# ddr32ss_EMIF_CTLCFG_0F308000h register map
Vendor: Texas Instruments
Registers are 32-bit, read-write, reset 0x0 unless marked. A register's access mark holds for its fields unless they carry their own. Offsets are as the file gives them; [hi:lo] are bit positions; lines under a group give offsets from that group; {n}, {i} and the like mark numbered series.

## emif_ctlcfg (part 4 of 13)
0x480 emif_ctlcfg_DENALI_CTL_288
  [31:0] BIST_DATA_MASK_1 — Mask applied to data for BIST error checking. Bit [0] controls memory data path bit [0], bit [1] controls memory data path bit [1], etc. Set each bit to 1 to mask. Reset Source: ctl_amod_g_rst_n
0x484 emif_ctlcfg_DENALI_CTL_289
  [2:0] BIST_TEST_MODE — Sets the BIST test mode. Value of 0 specifies standard BIST operation, value of 1 specifies a reduced BIST operation, value of 2 specifies a self-refresh retention test, value of 3 specifies an idle retention test, and value of 4 specifies memory initalization function. All other values are reserved. Reset Source: ctl_amod_g_rst_n
{0x0+4i} emif_ctlcfg_DENALI_CTL_{i} (i=290..293)
  [31:0] BIST_DATA_PATTERN_{i-290} — Data pattern to be used when the BIST_TEST_MODE parameter is programmed to 1, 2, 3 or 4. Only data corresponding to active portion of core word will be used while inactive portion will be ignored. Reset Source: ctl_amod_g_rst_n
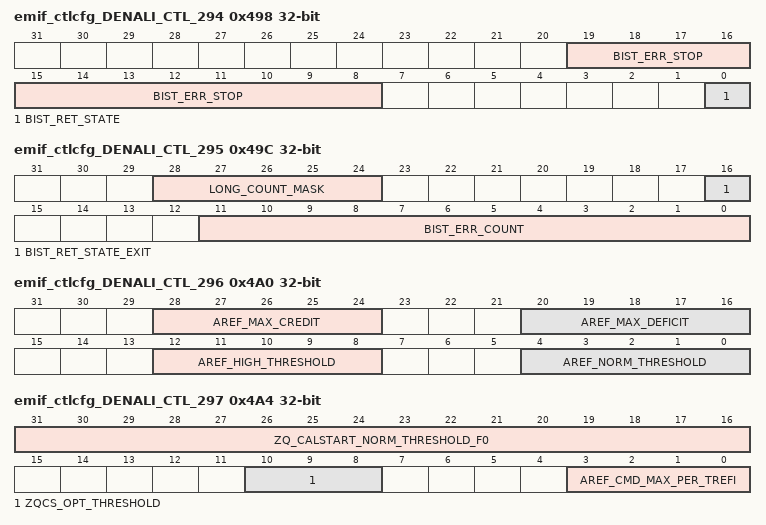
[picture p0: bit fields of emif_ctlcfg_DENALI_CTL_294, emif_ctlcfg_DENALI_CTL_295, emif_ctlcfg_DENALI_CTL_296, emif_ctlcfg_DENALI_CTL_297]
0x498 emif_ctlcfg_DENALI_CTL_294 access per field
  [19:8] BIST_ERR_STOP rw — Defines the maximum number of error occurrences allowed prior to quitting when the BIST_TEST_MODE parameter is programmed to 1, 2 or 3. A value of 0 will allow the test to run to completion. Reset Source: ctl_amod_g_rst_n
  [0] BIST_RET_STATE ro — Indicates if BIST is in a retention wait state, used when the BIST_TEST_MODE parameter is programmed to 2 or 3. Value of 1 indicates BIST is waiting. READ-ONLY Reset Source: ctl_amod_g_rst_n
0x49C emif_ctlcfg_DENALI_CTL_295 access per field
  [28:24] LONG_COUNT_MASK rw — Reduces the length of the long counter from 1024 cycles. The only supported values are 0x00 [1024 cycles], 0x10 [512 clocks], 0x18 [256 clocks], 0x1C [128 clocks], 0x1E [64 clocks] and 0x1F [32 clocks]. Reset Source: ctl_amod_g_rst_n
  [16] BIST_RET_STATE_EXIT wo — Exit self-refresh or idle retention state, used when the BIST_TEST_MODE parameter is programmed to 2 or 3. Set to 1 to trigger. WRITE-ONLY Reset Source: ctl_amod_g_rst_n
  [11:0] BIST_ERR_COUNT ro — Indicates the number of BIST errors found when the BIST_TEST_MODE parameter is programmed to 1, 2 or 3. READ-ONLY Reset Source: ctl_amod_g_rst_n
0x4A0 emif_ctlcfg_DENALI_CTL_296
  [28:24] AREF_MAX_CREDIT — AREF number of posted refreshes until the maximum number of refresh credits has been reached. Reset Source: ctl_amod_g_rst_n
  [20:16] AREF_MAX_DEFICIT — AREF number of pending refreshes until the maximum number of refreshes has been exceeded. Reset Source: ctl_amod_g_rst_n
  [12:8] AREF_HIGH_THRESHOLD — AREF number of pending refreshes until the high priority request is asserted. Reset Source: ctl_amod_g_rst_n
  [4:0] AREF_NORM_THRESHOLD — AREF number of pending refreshes until the normal priority request is asserted. Reset Source: ctl_amod_g_rst_n
0x4A4 emif_ctlcfg_DENALI_CTL_297
  [31:16] ZQ_CALSTART_NORM_THRESHOLD_F0 — ZQ START number of long counts until the normal priority request is asserted. This value should be scaled based on the number of ranks [chip selects] the controller handles. The more chip selects there are, the more rotations there are to go through, and the smaller this threshold should be. FC=0 Reset Source: ctl_amod_g_rst_n
  [10:8] ZQCS_OPT_THRESHOLD — Number of clocks before ZQCS expires when the ZQ task will deassert its request for optimal command to command turn-around timing. Reset Source: ctl_amod_g_rst_n
  [3:0] AREF_CMD_MAX_PER_TREFI — Sets the maximum number of auto-refreshes that will be executed in a TREFI period - both normal and high priority. This does not prevent refreshes generated by sub-task requests such as a self-refresh exit and enter. Reset Source: ctl_amod_g_rst_n
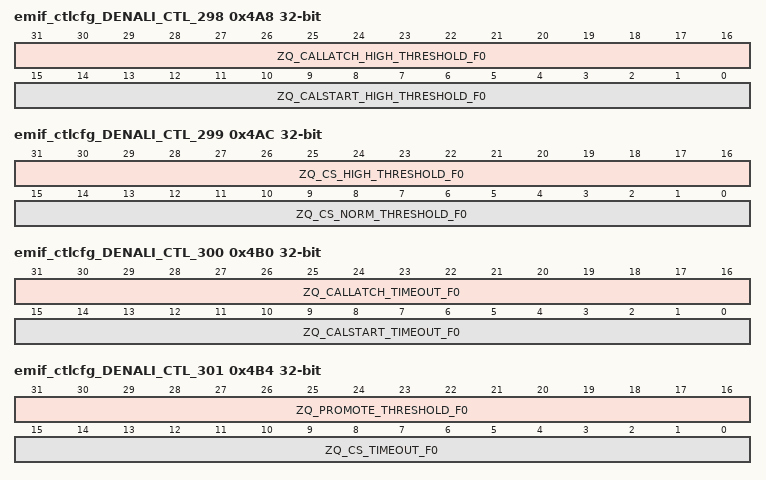
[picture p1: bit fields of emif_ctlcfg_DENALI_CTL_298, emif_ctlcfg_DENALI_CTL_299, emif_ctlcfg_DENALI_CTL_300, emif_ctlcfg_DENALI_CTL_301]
0x4A8 emif_ctlcfg_DENALI_CTL_298
  [31:16] ZQ_CALLATCH_HIGH_THRESHOLD_F0 — ZQ LATCH number of long counts until the high priority request is asserted. FC=0 Reset Source: ctl_amod_g_rst_n
  [15:0] ZQ_CALSTART_HIGH_THRESHOLD_F0 — ZQ START number of long counts until the high priority request is asserted. FC=0 Reset Source: ctl_amod_g_rst_n
0x4AC emif_ctlcfg_DENALI_CTL_299
  [31:16] ZQ_CS_HIGH_THRESHOLD_F0 — ZQ CS number of long counts until the high priority request is asserted. FC=0 Reset Source: ctl_amod_g_rst_n
  [15:0] ZQ_CS_NORM_THRESHOLD_F0 — ZQ CS number of long counts until the normal priority request is asserted. FC=0 Reset Source: ctl_amod_g_rst_n
0x4B0 emif_ctlcfg_DENALI_CTL_300
  [31:16] ZQ_CALLATCH_TIMEOUT_F0 — ZQ LATCH number of long counts until the timeout is asserted. FC=0 Reset Source: ctl_amod_g_rst_n
  [15:0] ZQ_CALSTART_TIMEOUT_F0 — ZQ START number of long counts until the timeout is asserted. FC=0 Reset Source: ctl_amod_g_rst_n
0x4B4 emif_ctlcfg_DENALI_CTL_301
  [31:16] ZQ_PROMOTE_THRESHOLD_F0 — ZQ SW promotion number of long counts until the high priority request is asserted. FC=0 Reset Source: ctl_amod_g_rst_n
  [15:0] ZQ_CS_TIMEOUT_F0 — ZQ CS number of long counts until the timeout is asserted. FC=0 Reset Source: ctl_amod_g_rst_n
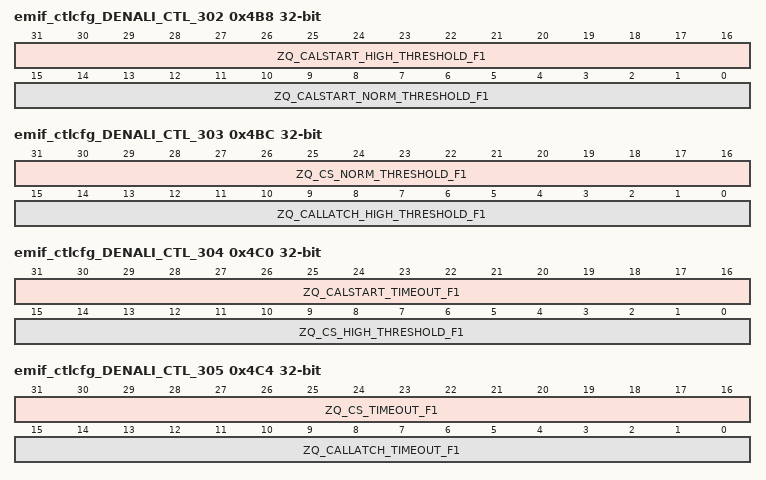
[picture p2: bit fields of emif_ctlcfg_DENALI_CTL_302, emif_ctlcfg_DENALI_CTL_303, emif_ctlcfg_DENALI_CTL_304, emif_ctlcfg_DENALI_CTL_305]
0x4B8 emif_ctlcfg_DENALI_CTL_302
  [31:16] ZQ_CALSTART_HIGH_THRESHOLD_F1 — ZQ START number of long counts until the high priority request is asserted. FC=1 Reset Source: ctl_amod_g_rst_n
  [15:0] ZQ_CALSTART_NORM_THRESHOLD_F1 — ZQ START number of long counts until the normal priority request is asserted. This value should be scaled based on the number of ranks [chip selects] the controller handles. The more chip selects there are, the more rotations there are to go through, and the smaller this threshold should be. FC=1 Reset Source: ctl_amod_g_rst_n
0x4BC emif_ctlcfg_DENALI_CTL_303
  [31:16] ZQ_CS_NORM_THRESHOLD_F1 — ZQ CS number of long counts until the normal priority request is asserted. FC=1 Reset Source: ctl_amod_g_rst_n
  [15:0] ZQ_CALLATCH_HIGH_THRESHOLD_F1 — ZQ LATCH number of long counts until the high priority request is asserted. FC=1 Reset Source: ctl_amod_g_rst_n
0x4C0 emif_ctlcfg_DENALI_CTL_304
  [31:16] ZQ_CALSTART_TIMEOUT_F1 — ZQ START number of long counts until the timeout is asserted. FC=1 Reset Source: ctl_amod_g_rst_n
  [15:0] ZQ_CS_HIGH_THRESHOLD_F1 — ZQ CS number of long counts until the high priority request is asserted. FC=1 Reset Source: ctl_amod_g_rst_n
0x4C4 emif_ctlcfg_DENALI_CTL_305
  [31:16] ZQ_CS_TIMEOUT_F1 — ZQ CS number of long counts until the timeout is asserted. FC=1 Reset Source: ctl_amod_g_rst_n
  [15:0] ZQ_CALLATCH_TIMEOUT_F1 — ZQ LATCH number of long counts until the timeout is asserted. FC=1 Reset Source: ctl_amod_g_rst_n
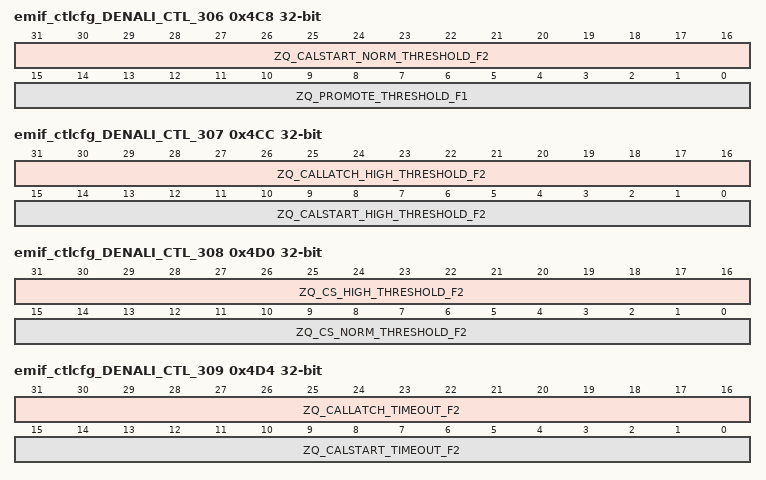
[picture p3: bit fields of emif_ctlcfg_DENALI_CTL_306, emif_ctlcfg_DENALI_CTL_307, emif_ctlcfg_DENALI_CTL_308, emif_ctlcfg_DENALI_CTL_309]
0x4C8 emif_ctlcfg_DENALI_CTL_306
  [31:16] ZQ_CALSTART_NORM_THRESHOLD_F2 — ZQ START number of long counts until the normal priority request is asserted. This value should be scaled based on the number of ranks [chip selects] the controller handles. The more chip selects there are, the more rotations there are to go through, and the smaller this threshold should be. FC=2 Reset Source: ctl_amod_g_rst_n
  [15:0] ZQ_PROMOTE_THRESHOLD_F1 — ZQ SW promotion number of long counts until the high priority request is asserted. FC=1 Reset Source: ctl_amod_g_rst_n
0x4CC emif_ctlcfg_DENALI_CTL_307
  [31:16] ZQ_CALLATCH_HIGH_THRESHOLD_F2 — ZQ LATCH number of long counts until the high priority request is asserted. FC=2 Reset Source: ctl_amod_g_rst_n
  [15:0] ZQ_CALSTART_HIGH_THRESHOLD_F2 — ZQ START number of long counts until the high priority request is asserted. FC=2 Reset Source: ctl_amod_g_rst_n
0x4D0 emif_ctlcfg_DENALI_CTL_308
  [31:16] ZQ_CS_HIGH_THRESHOLD_F2 — ZQ CS number of long counts until the high priority request is asserted. FC=2 Reset Source: ctl_amod_g_rst_n
  [15:0] ZQ_CS_NORM_THRESHOLD_F2 — ZQ CS number of long counts until the normal priority request is asserted. FC=2 Reset Source: ctl_amod_g_rst_n
0x4D4 emif_ctlcfg_DENALI_CTL_309
  [31:16] ZQ_CALLATCH_TIMEOUT_F2 — ZQ LATCH number of long counts until the timeout is asserted. FC=2 Reset Source: ctl_amod_g_rst_n
  [15:0] ZQ_CALSTART_TIMEOUT_F2 — ZQ START number of long counts until the timeout is asserted. FC=2 Reset Source: ctl_amod_g_rst_n
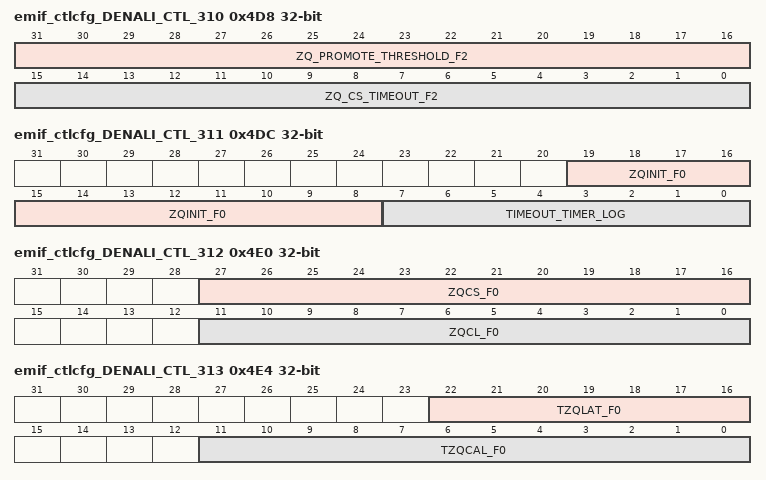
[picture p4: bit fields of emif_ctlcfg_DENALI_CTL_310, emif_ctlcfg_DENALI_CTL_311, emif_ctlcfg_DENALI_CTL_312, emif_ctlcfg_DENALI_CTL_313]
0x4D8 emif_ctlcfg_DENALI_CTL_310
  [31:16] ZQ_PROMOTE_THRESHOLD_F2 — ZQ SW promotion number of long counts until the high priority request is asserted. FC=2 Reset Source: ctl_amod_g_rst_n
  [15:0] ZQ_CS_TIMEOUT_F2 — ZQ CS number of long counts until the timeout is asserted. FC=2 Reset Source: ctl_amod_g_rst_n
0x4DC emif_ctlcfg_DENALI_CTL_311 access per field
  [19:8] ZQINIT_F0 rw — Number of cycles needed for a ZQINIT command. FC=0 Reset Source: ctl_amod_g_rst_n
  [7:0] TIMEOUT_TIMER_LOG ro — Reflects which timers experienced a timeout error [or had an uncleared error] when the timeout interrupt fired. Bit [0] correlates to a ZQ cal init, cs, cl, or reset FM timeout. Bit [1] correlates to the ZQ calstart FM timeout. Bit [2] correlates to the ZQ callatch FM timeout. Bit [3] correlates to the MRR temperature check FM timeout. Bit [4] correlates to the DQS oscillator FM timeout. Bit [5] correlates to the DFI update FM timeout. Bit [6] correlates to the low power interface wakeup timeout. Bit [7] correlates to the auto refresh max deficit timeout. READ-ONLY Reset Source: ctl_amod_g_rst_n
0x4E0 emif_ctlcfg_DENALI_CTL_312
  [27:16] ZQCS_F0 — Number of cycles needed for a ZQCS command. FC=0 Reset Source: ctl_amod_g_rst_n
  [11:0] ZQCL_F0 — Number of cycles needed for a ZQCL command. FC=0 Reset Source: ctl_amod_g_rst_n
0x4E4 emif_ctlcfg_DENALI_CTL_313
  [22:16] TZQLAT_F0 — Holds the DRAM ZQLAT value in cycles. FC=0 Reset Source: ctl_amod_g_rst_n
  [11:0] TZQCAL_F0 — Holds the DRAM ZQCAL value in cycles. FC=0 Reset Source: ctl_amod_g_rst_n
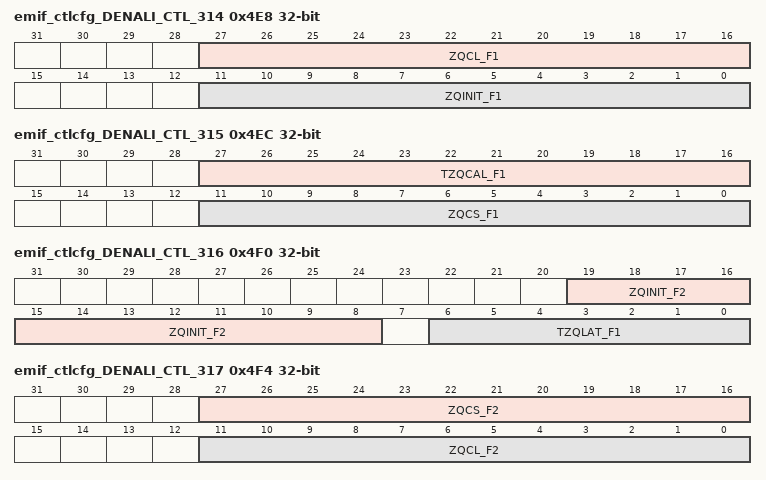
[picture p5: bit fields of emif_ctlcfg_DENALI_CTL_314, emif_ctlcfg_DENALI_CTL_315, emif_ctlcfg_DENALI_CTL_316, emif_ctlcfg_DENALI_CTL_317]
0x4E8 emif_ctlcfg_DENALI_CTL_314
  [27:16] ZQCL_F1 — Number of cycles needed for a ZQCL command. FC=1 Reset Source: ctl_amod_g_rst_n
  [11:0] ZQINIT_F1 — Number of cycles needed for a ZQINIT command. FC=1 Reset Source: ctl_amod_g_rst_n
0x4EC emif_ctlcfg_DENALI_CTL_315
  [27:16] TZQCAL_F1 — Holds the DRAM ZQCAL value in cycles. FC=1 Reset Source: ctl_amod_g_rst_n
  [11:0] ZQCS_F1 — Number of cycles needed for a ZQCS command. FC=1 Reset Source: ctl_amod_g_rst_n
0x4F0 emif_ctlcfg_DENALI_CTL_316
  [19:8] ZQINIT_F2 — Number of cycles needed for a ZQINIT command. FC=2 Reset Source: ctl_amod_g_rst_n
  [6:0] TZQLAT_F1 — Holds the DRAM ZQLAT value in cycles. FC=1 Reset Source: ctl_amod_g_rst_n
0x4F4 emif_ctlcfg_DENALI_CTL_317
  [27:16] ZQCS_F2 — Number of cycles needed for a ZQCS command. FC=2 Reset Source: ctl_amod_g_rst_n
  [11:0] ZQCL_F2 — Number of cycles needed for a ZQCL command. FC=2 Reset Source: ctl_amod_g_rst_n
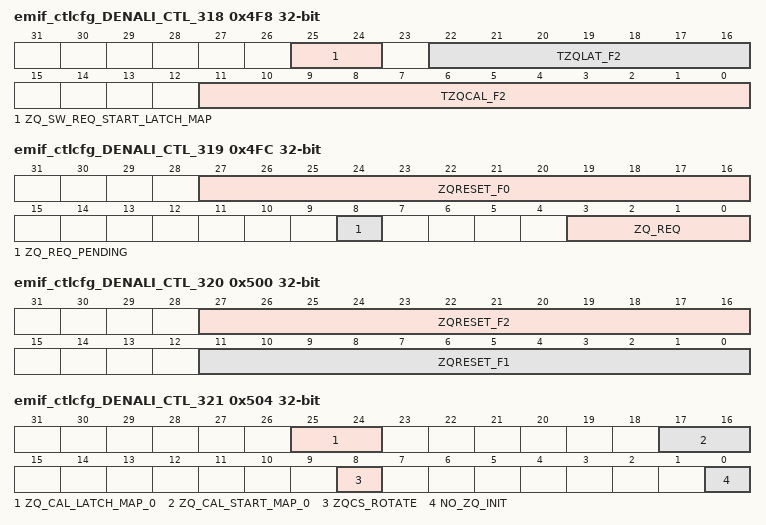
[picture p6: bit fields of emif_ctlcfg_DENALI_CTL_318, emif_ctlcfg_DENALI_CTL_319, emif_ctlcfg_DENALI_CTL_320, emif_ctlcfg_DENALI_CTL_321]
0x4F8 emif_ctlcfg_DENALI_CTL_318
  [25:24] ZQ_SW_REQ_START_LATCH_MAP — Specifies which chip selects will simultaneously receive a ZQ start or latch command once the ZQ_REQ parameter is written with a ZQ Start or ZQ Latch command. Reset Source: ctl_amod_g_rst_n
  [22:16] TZQLAT_F2 — Holds the DRAM ZQLAT value in cycles. FC=2 Reset Source: ctl_amod_g_rst_n
  [11:0] TZQCAL_F2 — Holds the DRAM ZQCAL value in cycles. FC=2 Reset Source: ctl_amod_g_rst_n
0x4FC emif_ctlcfg_DENALI_CTL_319 access per field
  [27:16] ZQRESET_F0 rw — Number of cycles needed for a ZQRESET command. FC=0 Reset Source: ctl_amod_g_rst_n
  [8] ZQ_REQ_PENDING ro — Indicates that a ZQ command is currently in progress or waiting to run. Value of 1 indicates command in progress or waiting to run. When this is asserted, no writes to ZQ_REQ should occur. READ-ONLY Reset Source: ctl_amod_g_rst_n
  [3:0] ZQ_REQ wo — User request to initiate a ZQ calibration. Program to 3 for ZQ Start, program to 4 for ZQ Initialization [ZQINIT], program to 5 for ZQ Latch, or program to 8 for ZQ Reset. Clearing to 0 will not trigger any ZQ command. This parameter should only be written when the ZQ_REQ_PENDING parameter is cleared to 0. WRITE-ONLY Reset Source: ctl_amod_g_rst_n
0x500 emif_ctlcfg_DENALI_CTL_320
  [27:16] ZQRESET_F2 — Number of cycles needed for a ZQRESET command. FC=2 Reset Source: ctl_amod_g_rst_n
  [11:0] ZQRESET_F1 — Number of cycles needed for a ZQRESET command. FC=1 Reset Source: ctl_amod_g_rst_n
0x504 emif_ctlcfg_DENALI_CTL_321
  [25:24] ZQ_CAL_LATCH_MAP_0 — Defines which chip select[s] will receive ZQ calibration latch commands simultaneously on iteration 0 of the ZQ LATCH initialization and periodic command sequences. Clear to all zeros for no ZQ LATCH commands. CS=0 Reset Source: ctl_amod_g_rst_n
  [17:16] ZQ_CAL_START_MAP_0 — Defines which chip select[s] will receive ZQ calibration start commands simultaneously on iteration 0 of the ZQ START initialization and periodic command sequences. Clear to all zeros for no ZQ START commands. CS=0 Reset Source: ctl_amod_g_rst_n
  [8] ZQCS_ROTATE — For memories that perform ZQ short commands [ZQCS], selects whether a ZQCS command will calibrate just one chip select or all chip selects. When rotation is off, all chip selects will be calibrated, requiring a longer time frame, but ZQ calibration will need to be performed less frequently. Set to 1 for rotating CS. For ZQ start/latch memories, this parameter is ignored. Reset Source: ctl_amod_g_rst_n
  [0] NO_ZQ_INIT — Disable ZQ operations during initialization. Set to 1 to disable. Reset Source: ctl_amod_g_rst_n
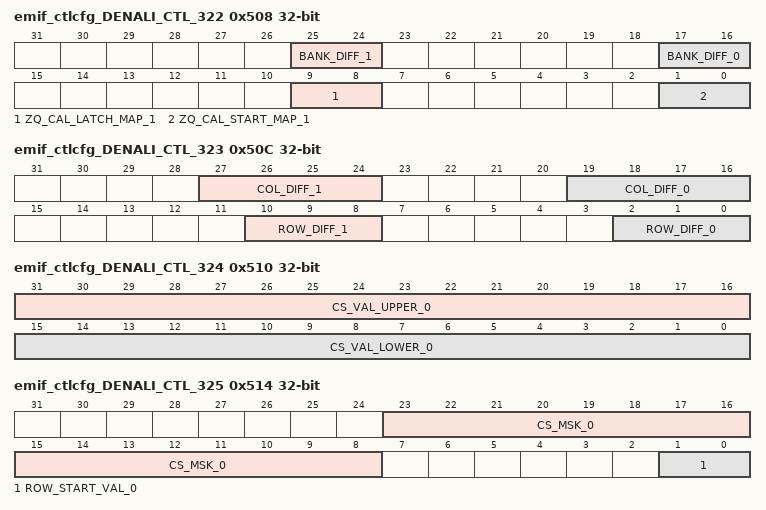
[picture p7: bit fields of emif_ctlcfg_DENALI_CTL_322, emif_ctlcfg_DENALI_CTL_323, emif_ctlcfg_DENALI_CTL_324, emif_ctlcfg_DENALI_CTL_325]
0x508 emif_ctlcfg_DENALI_CTL_322
  [25:24] BANK_DIFF_1 — Encoded number of banks on the DRAM[s]. Reset Source: ctl_amod_g_rst_n
  [17:16] BANK_DIFF_0 — Encoded number of banks on the DRAM[s]. Reset Source: ctl_amod_g_rst_n
  [9:8] ZQ_CAL_LATCH_MAP_1 — Defines which chip select[s] will receive ZQ calibration latch commands simultaneously on iteration 1 of the ZQ LATCH initialization and periodic command sequences. Clear to all zeros for no ZQ LATCH commands. CS=1 Reset Source: ctl_amod_g_rst_n
  [1:0] ZQ_CAL_START_MAP_1 — Defines which chip select[s] will receive ZQ calibration start commands simultaneously on iteration 1 of the ZQ START initialization and periodic command sequences. Clear to all zeros for no ZQ START commands. CS=1 Reset Source: ctl_amod_g_rst_n
0x50C emif_ctlcfg_DENALI_CTL_323
  [27:24] COL_DIFF_1 — Difference between number of column pins available and number being used. Reset Source: ctl_amod_g_rst_n
  [19:16] COL_DIFF_0 — Difference between number of column pins available and number being used. Reset Source: ctl_amod_g_rst_n
  [10:8] ROW_DIFF_1 — Difference between number of address pins available and number being used. Reset Source: ctl_amod_g_rst_n
  [2:0] ROW_DIFF_0 — Difference between number of address pins available and number being used. Reset Source: ctl_amod_g_rst_n
0x510 emif_ctlcfg_DENALI_CTL_324
  [31:16] CS_VAL_UPPER_0 — Upper bound address for chip select 0. Reset Source: ctl_amod_g_rst_n
  [15:0] CS_VAL_LOWER_0 — Lower bound address for chip select 0. Reset Source: ctl_amod_g_rst_n
0x514 emif_ctlcfg_DENALI_CTL_325
  [23:8] CS_MSK_0 — Mask applied to the address decode for chip select 0. Reset Source: ctl_amod_g_rst_n
  [1:0] ROW_START_VAL_0 — Row start value for chip select 0. Reset Source: ctl_amod_g_rst_n
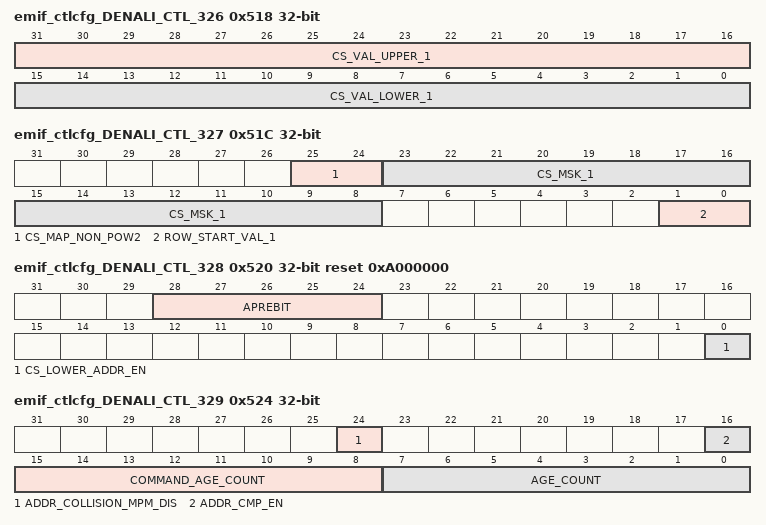
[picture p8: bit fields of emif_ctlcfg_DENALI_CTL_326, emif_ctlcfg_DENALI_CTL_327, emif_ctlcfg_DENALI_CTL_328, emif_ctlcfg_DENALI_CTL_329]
0x518 emif_ctlcfg_DENALI_CTL_326
  [31:16] CS_VAL_UPPER_1 — Upper bound address for chip select 1. Reset Source: ctl_amod_g_rst_n
  [15:0] CS_VAL_LOWER_1 — Lower bound address for chip select 1. Reset Source: ctl_amod_g_rst_n
0x51C emif_ctlcfg_DENALI_CTL_327
  [25:24] CS_MAP_NON_POW2 — Defines which chip selects are non-power-of-2 memory sizes. Reset Source: ctl_amod_g_rst_n
  [23:8] CS_MSK_1 — Mask applied to the address decode for chip select 1. Reset Source: ctl_amod_g_rst_n
  [1:0] ROW_START_VAL_1 — Row start value for chip select 1. Reset Source: ctl_amod_g_rst_n
0x520 emif_ctlcfg_DENALI_CTL_328 reset 0xA000000
  [28:24] APREBIT — Location of the auto pre-charge bit in the DRAM address. Reset Source: ctl_amod_g_rst_n
  [0] CS_LOWER_ADDR_EN — Enables moving the CS field to lower in the address map. When set to 1, the memory address map will be changed to ROW__CS__BANK. Please refer to the limitations before setting this bit. Reset Source: ctl_amod_g_rst_n
0x524 emif_ctlcfg_DENALI_CTL_329
  [24] ADDR_COLLISION_MPM_DIS — Disable address collision detection extension using micro page mask for command queue placement and selection. Set to 1 to disable. Reset Source: ctl_amod_g_rst_n
  [16] ADDR_CMP_EN — Enable address collision detection as a rule for command queue placement. Set to 1 to enable. Reset Source: ctl_amod_g_rst_n
  [15:8] COMMAND_AGE_COUNT — Initial value of individual command aging counters for command aging. Reset Source: ctl_amod_g_rst_n
  [7:0] AGE_COUNT — Initial value of master aging-rate counter for command aging. Reset Source: ctl_amod_g_rst_n
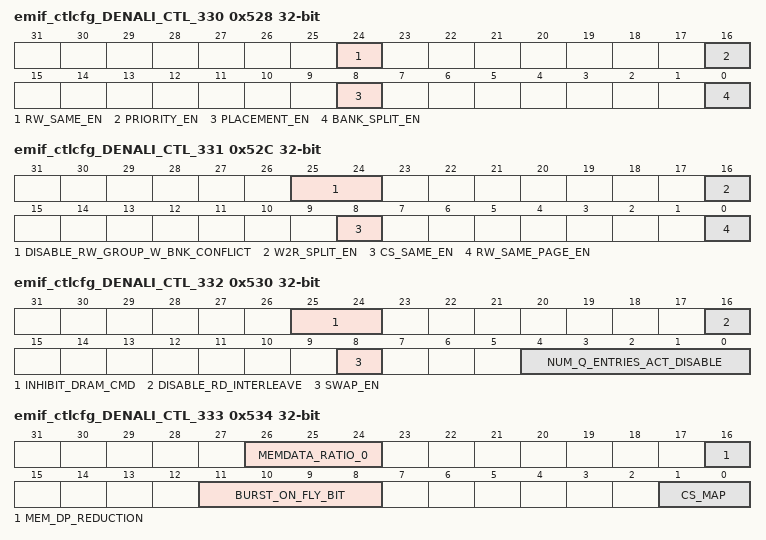
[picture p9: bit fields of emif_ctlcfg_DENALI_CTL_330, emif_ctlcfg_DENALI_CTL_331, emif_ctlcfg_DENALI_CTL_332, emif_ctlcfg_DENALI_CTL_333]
0x528 emif_ctlcfg_DENALI_CTL_330
  [24] RW_SAME_EN — Enable read/write grouping as a rule for command queue placement. Set to 1 to enable. Reset Source: ctl_amod_g_rst_n
  [16] PRIORITY_EN — Enable priority as a rule for command queue placement. Set to 1 to enable. Reset Source: ctl_amod_g_rst_n
  [8] PLACEMENT_EN — Enable placement logic for command queue. Set to 1 to enable. Reset Source: ctl_amod_g_rst_n
  [0] BANK_SPLIT_EN — Enable bank splitting as a rule for command queue placement. Set to 1 to enable. Reset Source: ctl_amod_g_rst_n
0x52C emif_ctlcfg_DENALI_CTL_331
  [25:24] DISABLE_RW_GROUP_W_BNK_CONFLICT — Disables placement to read/write group when grouping creates a bank collision. Bit [0] controls placement next to bank conflict command and bit [1] controls placement 2 away from bank conflict command. Set each bit to 1 to disable. Reset Source: ctl_amod_g_rst_n
  [16] W2R_SPLIT_EN — Enable splitting of commands to the same chip select from a write to a read command as a rule for command queue placement. Reset Source: ctl_amod_g_rst_n
  [8] CS_SAME_EN — Enable chip select grouping when read/write grouping as a rule for command queue placement. This is only valid when the RW_SAME_EN parameter is set. Set to 1 to enable. Reset Source: ctl_amod_g_rst_n
  [0] RW_SAME_PAGE_EN — Enable page grouping when read/write grouping as a rule for command queue placement. This is only valid when the RW_SAME_EN parameter is set. Set to 1 to enable. Reset Source: ctl_amod_g_rst_n
0x530 emif_ctlcfg_DENALI_CTL_332
  [25:24] INHIBIT_DRAM_CMD — Inhibit command types from being executed from the command queue. Clear to 0 to enable any command, program to 1 to inhibit read/write and bank commands, program to 2 to inhibit MRR and peripheral MRR commands, or program to 3 to inhibit MRR and read/write commands. Reset Source: ctl_amod_g_rst_n
  [16] DISABLE_RD_INTERLEAVE — Disable read data interleaving for commands from the same port, regardless of the requestor ID. Reset Source: ctl_amod_g_rst_n
  [8] SWAP_EN — Enable command swapping logic in execution unit. Set to 1 to enable. Reset Source: ctl_amod_g_rst_n
  [4:0] NUM_Q_ENTRIES_ACT_DISABLE — Number of queue entries in which ACT requests will be disabled. Programming to X will disable ACT requests from the X entries lowest in the command queue. Reset Source: ctl_amod_g_rst_n
0x534 emif_ctlcfg_DENALI_CTL_333
  [26:24] MEMDATA_RATIO_0 — Defines the ratio of the DRAM device size on chip select 0 to the memory data width. Program with the log2 ratio of the memory data width to the device data width. CS=0 Reset Source: ctl_amod_g_rst_n
  [16] MEM_DP_REDUCTION — Enable the half datapath feature of the controller. Set to 1 to enable. Reset Source: ctl_amod_g_rst_n
  [11:8] BURST_ON_FLY_BIT — Identifies the burst-on-fly bit in the memory mode registers. Reset Source: ctl_amod_g_rst_n
  [1:0] CS_MAP — Defines which chip selects are active. Reset Source: ctl_amod_g_rst_n
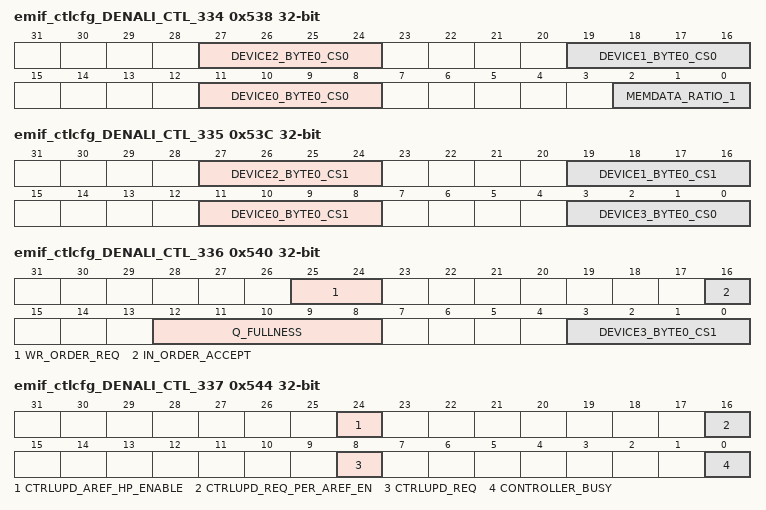
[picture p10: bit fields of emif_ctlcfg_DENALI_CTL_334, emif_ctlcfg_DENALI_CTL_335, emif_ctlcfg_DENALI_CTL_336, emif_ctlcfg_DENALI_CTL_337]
0x538 emif_ctlcfg_DENALI_CTL_334
  [27:24] DEVICE2_BYTE0_CS0 — Defines the byte location of byte0 in the memory datapath for device 2 on chip 0. Used for MRRs to identify where data will be returned. DEV=2 Reset Source: ctl_amod_g_rst_n
  [19:16] DEVICE1_BYTE0_CS0 — Defines the byte location of byte0 in the memory datapath for device 1 on chip 0. Used for MRRs to identify where data will be returned. DEV=1 Reset Source: ctl_amod_g_rst_n
  [11:8] DEVICE0_BYTE0_CS0 — Defines the byte location of byte0 in the memory datapath for device 0 on chip 0. Used for MRRs to identify where data will be returned. DEV=0 Reset Source: ctl_amod_g_rst_n
  [2:0] MEMDATA_RATIO_1 — Defines the ratio of the DRAM device size on chip select 1 to the memory data width. Program with the log2 ratio of the memory data width to the device data width. CS=1 Reset Source: ctl_amod_g_rst_n
0x53C emif_ctlcfg_DENALI_CTL_335
  [27:24] DEVICE2_BYTE0_CS1 — Defines the byte location of byte0 in the memory datapath for device 2 on chip 1. Used for MRRs to identify where data will be returned. DEV=2 Reset Source: ctl_amod_g_rst_n
  [19:16] DEVICE1_BYTE0_CS1 — Defines the byte location of byte0 in the memory datapath for device 1 on chip 1. Used for MRRs to identify where data will be returned. DEV=1 Reset Source: ctl_amod_g_rst_n
  [11:8] DEVICE0_BYTE0_CS1 — Defines the byte location of byte0 in the memory datapath for device 0 on chip 1. Used for MRRs to identify where data will be returned. DEV=0 Reset Source: ctl_amod_g_rst_n
  [3:0] DEVICE3_BYTE0_CS0 — Defines the byte location of byte0 in the memory datapath for device 3 on chip 0. Used for MRRs to identify where data will be returned. DEV=3 Reset Source: ctl_amod_g_rst_n
0x540 emif_ctlcfg_DENALI_CTL_336
  [25:24] WR_ORDER_REQ — Determines if the controller can re-order write commands from the same source ID and/or the same port. Bit [0] controls source ID usage and bit [1] controls port ID usage. Set each bit to 1 to enable usage in placement logic. Reset Source: ctl_amod_g_rst_n
  [16] IN_ORDER_ACCEPT — Forces the controller to accept commands in the order in which they are placed in the command queue. Reset Source: ctl_amod_g_rst_n
  [12:8] Q_FULLNESS — Quantity that determines when the command queue almost full signal will assert [q_almost_full]. When cleared to 0, the q_almost_full signal will be driven to 0 irrespective of number of entries in the command queue. Reset Source: ctl_amod_g_rst_n
  [3:0] DEVICE3_BYTE0_CS1 — Defines the byte location of byte0 in the memory datapath for device 3 on chip 1. Used for MRRs to identify where data will be returned. DEV=3 Reset Source: ctl_amod_g_rst_n
0x544 emif_ctlcfg_DENALI_CTL_337 access per field
  [24] CTRLUPD_AREF_HP_ENABLE rw — Enable an automatic controller-initiated update [dfi_ctrlupd_req] after every high priority refresh when executing as a subtask request. Set to 1 to enable. Reset Source: ctl_amod_g_rst_n
  [16] CTRLUPD_REQ_PER_AREF_EN rw — Enable an automatic controller-initiated update [dfi_ctrlupd_req] after every refresh. Set to 1 to enable. Reset Source: ctl_amod_g_rst_n
  [8] CTRLUPD_REQ wo — Assert the DFI controller-initiated update request signal dfi_ctrlupd_req. Set to 1 to trigger. WRITE-ONLY Reset Source: ctl_amod_g_rst_n
  [0] CONTROLLER_BUSY ro — Indicator that the controller is processing a command. Evaluates all ports for outstanding transactions. Value of 1 indicates controller busy. READ-ONLY Reset Source: ctl_amod_g_rst_n
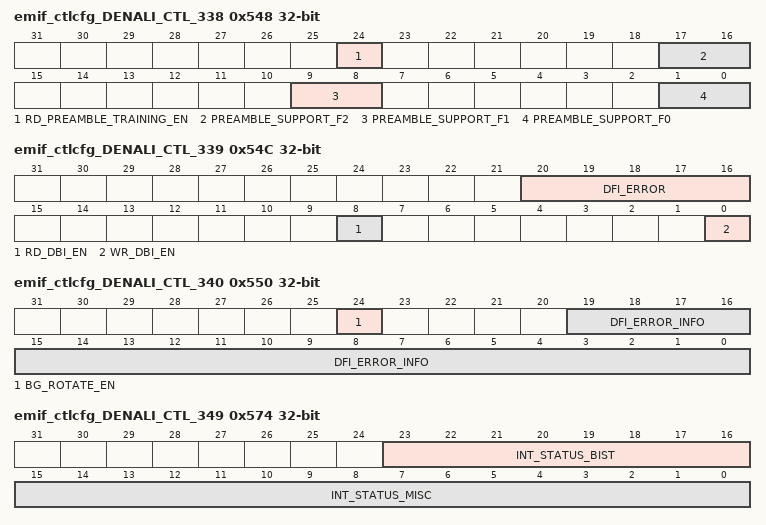
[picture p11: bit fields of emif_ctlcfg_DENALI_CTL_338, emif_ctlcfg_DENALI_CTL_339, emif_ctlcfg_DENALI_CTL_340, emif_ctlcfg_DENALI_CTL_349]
0x548 emif_ctlcfg_DENALI_CTL_338
  [24] RD_PREAMBLE_TRAINING_EN — Enable read preamble training during gate training. Set to 1 to enable. Reset Source: ctl_amod_g_rst_n
  [17:16] PREAMBLE_SUPPORT_F2 — Selection the preamble for read and write burst transfers. FC=2 Reset Source: ctl_amod_g_rst_n
  [9:8] PREAMBLE_SUPPORT_F1 — Selection the preamble for read and write burst transfers. FC=1 Reset Source: ctl_amod_g_rst_n
  [1:0] PREAMBLE_SUPPORT_F0 — Selection the preamble for read and write burst transfers. FC=0 Reset Source: ctl_amod_g_rst_n
0x54C emif_ctlcfg_DENALI_CTL_339 access per field
  [20:16] DFI_ERROR ro — Indicates that the DFI error flag has been asserted. READ-ONLY Reset Source: ctl_amod_g_rst_n
  [8] RD_DBI_EN rw — Enables controller support of DRAM DBI feature for read data with DDR4 devices. Set to 1 to enable. Reset Source: ctl_amod_g_rst_n
  [0] WR_DBI_EN rw — Enables controller support of DRAM DBI feature for write data with DDR4 devices. Set to 1 to enable. Reset Source: ctl_amod_g_rst_n
0x550 emif_ctlcfg_DENALI_CTL_340 access per field
  [24] BG_ROTATE_EN rw — Enable bank group rotation. Set to 1 to enable. Reset Source: ctl_amod_g_rst_n
  [19:0] DFI_ERROR_INFO ro — Holds the encoded DFI error type associated with the DFI_ERROR parameter assertion. READ-ONLY Reset Source: ctl_amod_g_rst_n
0x554 emif_ctlcfg_DENALI_CTL_341 access not given reset not defined
0x558 emif_ctlcfg_DENALI_CTL_342 ro
  [31:0] INT_STATUS_MASTER — Master status reporting register for interrupt status groups. READ-ONLY Reset Source: ctl_amod_g_rst_n
0x55C emif_ctlcfg_DENALI_CTL_343
  [31:0] INT_MASK_MASTER — Master mask register for interrupt status groups. WRITE-ONLY Reset Source: ctl_amod_g_rst_n
0x560 emif_ctlcfg_DENALI_CTL_344 ro
  [31:0] INT_STATUS_TIMEOUT — Status of interrupts in the controller related to Timeout monitors. READ-ONLY Reset Source: ctl_amod_g_rst_n
0x564 emif_ctlcfg_DENALI_CTL_345 ro
  [31:16] INT_STATUS_LOWPOWER — Status of interrupts in the controller related to Low Power. READ-ONLY Reset Source: ctl_amod_g_rst_n
0x568 emif_ctlcfg_DENALI_CTL_346 access not given reset not defined
0x56C emif_ctlcfg_DENALI_CTL_347 ro
  [31:0] INT_STATUS_TRAINING — Status of interrupts in the controller related to Training/Calibration. READ-ONLY Reset Source: ctl_amod_g_rst_n
0x570 emif_ctlcfg_DENALI_CTL_348 ro
  [31:0] INT_STATUS_USERIF — Status of interrupts in the controller related to ASIC to Controller Interface. READ-ONLY Reset Source: ctl_amod_g_rst_n
0x574 emif_ctlcfg_DENALI_CTL_349 ro
  [23:16] INT_STATUS_BIST — Status of interrupts in the controller related to BIST. READ-ONLY Reset Source: ctl_amod_g_rst_n
  [15:0] INT_STATUS_MISC — Status of interrupts in the controller related to Miscellaneous features. READ-ONLY Reset Source: ctl_amod_g_rst_n
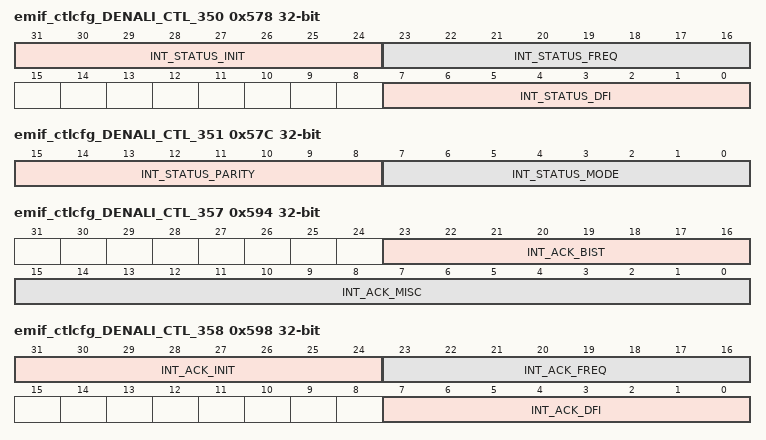
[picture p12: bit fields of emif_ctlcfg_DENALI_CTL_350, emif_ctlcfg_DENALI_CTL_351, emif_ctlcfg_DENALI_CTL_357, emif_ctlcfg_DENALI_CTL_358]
0x578 emif_ctlcfg_DENALI_CTL_350 ro
  [31:24] INT_STATUS_INIT — Status of interrupts in the controller related to Initialization. READ-ONLY Reset Source: ctl_amod_g_rst_n
  [23:16] INT_STATUS_FREQ — Status of interrupts in the controller related to Frequency Scaling. READ-ONLY Reset Source: ctl_amod_g_rst_n
  [7:0] INT_STATUS_DFI — Status of interrupts in the controller related to DFI. READ-ONLY Reset Source: ctl_amod_g_rst_n
0x57C emif_ctlcfg_DENALI_CTL_351 ro
  [15:8] INT_STATUS_PARITY — Status of interrupts in the controller related to Parity. READ-ONLY Reset Source: ctl_amod_g_rst_n
  [7:0] INT_STATUS_MODE — Status of interrupts in the controller related to Memory Mode Settings. READ-ONLY Reset Source: ctl_amod_g_rst_n
0x580 emif_ctlcfg_DENALI_CTL_352 wo
  [31:0] INT_ACK_TIMEOUT — Clear status of the INT_STATUS_TIMEOUT parameter. WRITE-ONLY Reset Source: ctl_amod_g_rst_n
0x584 emif_ctlcfg_DENALI_CTL_353 wo
  [31:16] INT_ACK_LOWPOWER — Clear status of the INT_STATUS_LOWPOWER parameter. WRITE-ONLY Reset Source: ctl_amod_g_rst_n
0x588 emif_ctlcfg_DENALI_CTL_354 access not given reset not defined
0x58C emif_ctlcfg_DENALI_CTL_355 wo
  [31:0] INT_ACK_TRAINING — Clear status of the INT_STATUS_TRAINING parameter. WRITE-ONLY Reset Source: ctl_amod_g_rst_n
0x590 emif_ctlcfg_DENALI_CTL_356 wo
  [31:0] INT_ACK_USERIF — Clear status of the INT_STATUS_USERIF parameter. WRITE-ONLY Reset Source: ctl_amod_g_rst_n
0x594 emif_ctlcfg_DENALI_CTL_357 wo
  [23:16] INT_ACK_BIST — Clear status of the INT_STATUS_BIST parameter. WRITE-ONLY Reset Source: ctl_amod_g_rst_n
  [15:0] INT_ACK_MISC — Clear status of the INT_STATUS_MISC parameter. WRITE-ONLY Reset Source: ctl_amod_g_rst_n
0x598 emif_ctlcfg_DENALI_CTL_358 wo
  [31:24] INT_ACK_INIT — Clear status of the INT_STATUS_INIT parameter. WRITE-ONLY Reset Source: ctl_amod_g_rst_n
  [23:16] INT_ACK_FREQ — Clear status of the INT_STATUS_FREQ parameter. WRITE-ONLY Reset Source: ctl_amod_g_rst_n
  [7:0] INT_ACK_DFI — Clear status of the INT_STATUS_DFI parameter. WRITE-ONLY Reset Source: ctl_amod_g_rst_n
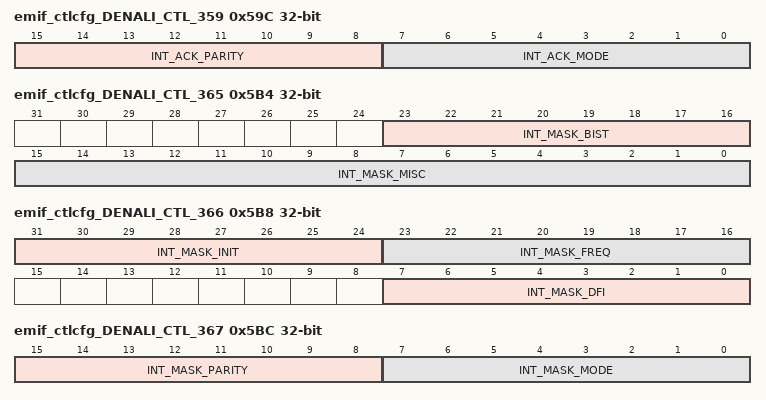
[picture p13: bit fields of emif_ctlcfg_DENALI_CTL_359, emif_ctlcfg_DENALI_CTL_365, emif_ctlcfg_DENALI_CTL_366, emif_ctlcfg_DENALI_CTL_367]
0x59C emif_ctlcfg_DENALI_CTL_359 wo
  [15:8] INT_ACK_PARITY — Clear status of the INT_STATUS_PARITY parameter. WRITE-ONLY Reset Source: ctl_amod_g_rst_n
  [7:0] INT_ACK_MODE — Clear status of the INT_STATUS_MODE parameter. WRITE-ONLY Reset Source: ctl_amod_g_rst_n
0x5A0 emif_ctlcfg_DENALI_CTL_360
  [31:0] INT_MASK_TIMEOUT — Mask for the controller_int signal from the INT_MASK_TIMEOUT parameter Reset Source: ctl_amod_g_rst_n
0x5A4 emif_ctlcfg_DENALI_CTL_361
  [31:16] INT_MASK_LOWPOWER — Mask for the controller_int signal from the INT_MASK_LOWPOWER parameter Reset Source: ctl_amod_g_rst_n
0x5A8 emif_ctlcfg_DENALI_CTL_362 access not given reset not defined
0x5AC emif_ctlcfg_DENALI_CTL_363
  [31:0] INT_MASK_TRAINING — Mask for the controller_int signal from the INT_MASK_TRAINING parameter Reset Source: ctl_amod_g_rst_n
0x5B0 emif_ctlcfg_DENALI_CTL_364
  [31:0] INT_MASK_USERIF — Mask for the controller_int signal from the INT_MASK_USERIF parameter Reset Source: ctl_amod_g_rst_n
0x5B4 emif_ctlcfg_DENALI_CTL_365
  [23:16] INT_MASK_BIST — Mask for the controller_int signal from the INT_MASK_BIST parameter Reset Source: ctl_amod_g_rst_n
  [15:0] INT_MASK_MISC — Mask for the controller_int signal from the INT_MASK_MISC parameter Reset Source: ctl_amod_g_rst_n
0x5B8 emif_ctlcfg_DENALI_CTL_366
  [31:24] INT_MASK_INIT — Mask for the controller_int signal from the INT_MASK_INIT parameter Reset Source: ctl_amod_g_rst_n
  [23:16] INT_MASK_FREQ — Mask for the controller_int signal from the INT_MASK_FREQ parameter Reset Source: ctl_amod_g_rst_n
  [7:0] INT_MASK_DFI — Mask for the controller_int signal from the INT_MASK_DFI parameter Reset Source: ctl_amod_g_rst_n
0x5BC emif_ctlcfg_DENALI_CTL_367
  [15:8] INT_MASK_PARITY — Mask for the controller_int signal from the INT_MASK_PARITY parameter Reset Source: ctl_amod_g_rst_n
  [7:0] INT_MASK_MODE — Mask for the controller_int signal from the INT_MASK_MODE parameter Reset Source: ctl_amod_g_rst_n
0x5C0 emif_ctlcfg_DENALI_CTL_368 ro
  [31:0] OUT_OF_RANGE_ADDR_0 — Address of command that caused an out-of-range interrupt. READ-ONLY Reset Source: ctl_amod_g_rst_n
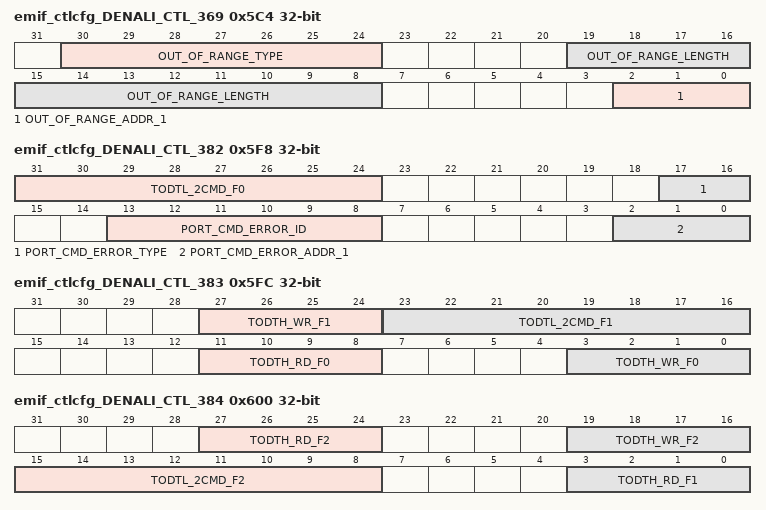
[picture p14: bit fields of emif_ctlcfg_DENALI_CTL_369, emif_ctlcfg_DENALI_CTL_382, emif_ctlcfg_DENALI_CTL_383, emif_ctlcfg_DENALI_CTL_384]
0x5C4 emif_ctlcfg_DENALI_CTL_369 ro
  [30:24] OUT_OF_RANGE_TYPE — Type of command that caused an out-of-range interrupt. READ-ONLY Reset Source: ctl_amod_g_rst_n
  [19:8] OUT_OF_RANGE_LENGTH — Length of command that caused an out-of-range interrupt. READ-ONLY Reset Source: ctl_amod_g_rst_n
  [2:0] OUT_OF_RANGE_ADDR_1 — Address of command that caused an out-of-range interrupt. READ-ONLY Reset Source: ctl_amod_g_rst_n
0x5C8 emif_ctlcfg_DENALI_CTL_370 ro
  [5:0] OUT_OF_RANGE_SOURCE_ID — Source ID of command that caused an out-of-range interrupt. READ-ONLY Reset Source: ctl_amod_g_rst_n
{0x0+4i} emif_ctlcfg_DENALI_CTL_{i} ro (i=371..374)
  [31:0] BIST_EXP_DATA_{i-371} — Expected data on BIST error. READ-ONLY Reset Source: ctl_amod_g_rst_n
{0x0+4i} emif_ctlcfg_DENALI_CTL_{i} ro (i=375..378)
  [31:0] BIST_FAIL_DATA_{i-375} — Actual data on BIST error. READ-ONLY Reset Source: ctl_amod_g_rst_n
0x5EC emif_ctlcfg_DENALI_CTL_379 ro
  [31:0] BIST_FAIL_ADDR_0 — Address of BIST error. READ-ONLY Reset Source: ctl_amod_g_rst_n
0x5F0 emif_ctlcfg_DENALI_CTL_380 ro
  [2:0] BIST_FAIL_ADDR_1 — Address of BIST error. READ-ONLY Reset Source: ctl_amod_g_rst_n
0x5F4 emif_ctlcfg_DENALI_CTL_381 ro
  [31:0] PORT_CMD_ERROR_ADDR_0 — Address of command that caused the PORT command error. READ-ONLY Reset Source: ctl_amod_g_rst_n
0x5F8 emif_ctlcfg_DENALI_CTL_382 access per field
  [31:24] TODTL_2CMD_F0 rw — Defines the DRAM delay from an ODT de-assertion to the next non-write, non-read command. FC=0 Reset Source: ctl_amod_g_rst_n
  [17:16] PORT_CMD_ERROR_TYPE ro — Type of error and access type that caused the PORT command error. READ-ONLY Reset Source: ctl_amod_g_rst_n
  [13:8] PORT_CMD_ERROR_ID ro — Source ID of command that caused the PORT command error. READ-ONLY Reset Source: ctl_amod_g_rst_n
  [2:0] PORT_CMD_ERROR_ADDR_1 ro — Address of command that caused the PORT command error. READ-ONLY Reset Source: ctl_amod_g_rst_n
0x5FC emif_ctlcfg_DENALI_CTL_383
  [27:24] TODTH_WR_F1 — Defines the DRAM minimum ODT high time after an ODT assertion for a write command. FC=1 Reset Source: ctl_amod_g_rst_n
  [23:16] TODTL_2CMD_F1 — Defines the DRAM delay from an ODT de-assertion to the next non-write, non-read command. FC=1 Reset Source: ctl_amod_g_rst_n
  [11:8] TODTH_RD_F0 — Defines the DRAM minimum ODT high time after an ODT assertion for a read command. FC=0 Reset Source: ctl_amod_g_rst_n
  [3:0] TODTH_WR_F0 — Defines the DRAM minimum ODT high time after an ODT assertion for a write command. FC=0 Reset Source: ctl_amod_g_rst_n
0x600 emif_ctlcfg_DENALI_CTL_384
  [27:24] TODTH_RD_F2 — Defines the DRAM minimum ODT high time after an ODT assertion for a read command. FC=2 Reset Source: ctl_amod_g_rst_n
  [19:16] TODTH_WR_F2 — Defines the DRAM minimum ODT high time after an ODT assertion for a write command. FC=2 Reset Source: ctl_amod_g_rst_n
  [15:8] TODTL_2CMD_F2 — Defines the DRAM delay from an ODT de-assertion to the next non-write, non-read command. FC=2 Reset Source: ctl_amod_g_rst_n
  [3:0] TODTH_RD_F1 — Defines the DRAM minimum ODT high time after an ODT assertion for a read command. FC=1 Reset Source: ctl_amod_g_rst_n
0x604 emif_ctlcfg_DENALI_CTL_385
  [24] EN_ODT_ASSERT_EXCEPT_RD — Enable controller to assert ODT at all times except during reads. Assumes single ODT pin connected. Set to 1 to enable. Reset Source: ctl_amod_g_rst_n
  [16] ODT_EN_F2 — Enable support of DRAM ODT. When enabled, controller will assert and de-assert ODT output to DRAM as needed. FC=2 Reset Source: ctl_amod_g_rst_n
  [8] ODT_EN_F1 — Enable support of DRAM ODT. When enabled, controller will assert and de-assert ODT output to DRAM as needed. FC=1 Reset Source: ctl_amod_g_rst_n
  [0] ODT_EN_F0 — Enable support of DRAM ODT. When enabled, controller will assert and de-assert ODT output to DRAM as needed. FC=0 Reset Source: ctl_amod_g_rst_n
0x608 emif_ctlcfg_DENALI_CTL_386
  [25:24] ODT_RD_MAP_CS0 — Determines which chip[s] will have termination when a read occurs. Set bit X to enable termination on csX when a read is performed. CS=0 Reset Source: ctl_amod_g_rst_n
  [21:16] WR_TO_ODTH_F2 — Defines the delay from a write command to ODT assertion. FC=2 Reset Source: ctl_amod_g_rst_n
  [13:8] WR_TO_ODTH_F1 — Defines the delay from a write command to ODT assertion. FC=1 Reset Source: ctl_amod_g_rst_n
  [5:0] WR_TO_ODTH_F0 — Defines the delay from a write command to ODT assertion. FC=0 Reset Source: ctl_amod_g_rst_n
0x60C emif_ctlcfg_DENALI_CTL_387
  [29:24] RD_TO_ODTH_F0 — Defines the delay from a read command to ODT assertion. FC=0 Reset Source: ctl_amod_g_rst_n
  [17:16] ODT_WR_MAP_CS1 — Determines which chip[s] will have termination when a write occurs. Set bit X to enable termination on csX when a write is performed. CS=1 Reset Source: ctl_amod_g_rst_n
  [9:8] ODT_RD_MAP_CS1 — Determines which chip[s] will have termination when a read occurs. Set bit X to enable termination on csX when a read is performed. CS=1 Reset Source: ctl_amod_g_rst_n
  [1:0] ODT_WR_MAP_CS0 — Determines which chip[s] will have termination when a write occurs. Set bit X to enable termination on csX when a write is performed. CS=0 Reset Source: ctl_amod_g_rst_n
0x610 emif_ctlcfg_DENALI_CTL_388 reset 0x8080000
  [28:24] RW2MRW_DLY_F1 — Additional delay to insert between read or write and mode_reg_write. Allowed programming dependent on memory system. FC=1 Reset Source: ctl_amod_g_rst_n
  [20:16] RW2MRW_DLY_F0 — Additional delay to insert between read or write and mode_reg_write. Allowed programming dependent on memory system. FC=0 Reset Source: ctl_amod_g_rst_n
  [13:8] RD_TO_ODTH_F2 — Defines the delay from a read command to ODT assertion. FC=2 Reset Source: ctl_amod_g_rst_n
  [5:0] RD_TO_ODTH_F1 — Defines the delay from a read command to ODT assertion. FC=1 Reset Source: ctl_amod_g_rst_n
0x614 emif_ctlcfg_DENALI_CTL_389 reset 0x1010108
  [28:24] W2R_DIFFCS_DLY_F0 — Additional delay to insert between writes and reads to different chip selects. Allowed programming dependent on memory system. FC=0 Reset Source: ctl_amod_g_rst_n
  [20:16] R2W_DIFFCS_DLY_F0 — Additional delay to insert between reads and writes to different chip selects. Program to a non-zero value. FC=0 Reset Source: ctl_amod_g_rst_n
  [12:8] R2R_DIFFCS_DLY_F0 — Additional delay to insert between reads to different chip selects. Program to a non-zero value. FC=0 Reset Source: ctl_amod_g_rst_n
  [4:0] RW2MRW_DLY_F2 — Additional delay to insert between read or write and mode_reg_write. Allowed programming dependent on memory system. FC=2 Reset Source: ctl_amod_g_rst_n
0x618 emif_ctlcfg_DENALI_CTL_390 reset 0x1010101
  [28:24] W2R_DIFFCS_DLY_F1 — Additional delay to insert between writes and reads to different chip selects. Allowed programming dependent on memory system. FC=1 Reset Source: ctl_amod_g_rst_n
  [20:16] R2W_DIFFCS_DLY_F1 — Additional delay to insert between reads and writes to different chip selects. Program to a non-zero value. FC=1 Reset Source: ctl_amod_g_rst_n
  [12:8] R2R_DIFFCS_DLY_F1 — Additional delay to insert between reads to different chip selects. Program to a non-zero value. FC=1 Reset Source: ctl_amod_g_rst_n
  [4:0] W2W_DIFFCS_DLY_F0 — Additional delay to insert between writes to different chip selects. Program to a non-zero value. FC=0 Reset Source: ctl_amod_g_rst_n
0x61C emif_ctlcfg_DENALI_CTL_391 reset 0x1010101
  [28:24] W2R_DIFFCS_DLY_F2 — Additional delay to insert between writes and reads to different chip selects. Allowed programming dependent on memory system. FC=2 Reset Source: ctl_amod_g_rst_n
  [20:16] R2W_DIFFCS_DLY_F2 — Additional delay to insert between reads and writes to different chip selects. Program to a non-zero value. FC=2 Reset Source: ctl_amod_g_rst_n
  [12:8] R2R_DIFFCS_DLY_F2 — Additional delay to insert between reads to different chip selects. Program to a non-zero value. FC=2 Reset Source: ctl_amod_g_rst_n
  [4:0] W2W_DIFFCS_DLY_F1 — Additional delay to insert between writes to different chip selects. Program to a non-zero value. FC=1 Reset Source: ctl_amod_g_rst_n
0x620 emif_ctlcfg_DENALI_CTL_392 reset 0x2020201
  [28:24] R2W_SAMECS_DLY_F2 — Additional delay to insert between reads and writes to the same chip select. Program to a non-zero value. FC=2 Reset Source: ctl_amod_g_rst_n
  [20:16] R2W_SAMECS_DLY_F1 — Additional delay to insert between reads and writes to the same chip select. Program to a non-zero value. FC=1 Reset Source: ctl_amod_g_rst_n
  [12:8] R2W_SAMECS_DLY_F0 — Additional delay to insert between reads and writes to the same chip select. Program to a non-zero value. FC=0 Reset Source: ctl_amod_g_rst_n
  [4:0] W2W_DIFFCS_DLY_F2 — Additional delay to insert between writes to different chip selects. Program to a non-zero value. FC=2 Reset Source: ctl_amod_g_rst_n
0x624 emif_ctlcfg_DENALI_CTL_393
  [27:24] TDQSCK_MAX_F0 — Additional delay needed for tDQSCK. FC=0 Reset Source: ctl_amod_g_rst_n
  [20:16] W2W_SAMECS_DLY — Additional delay to insert between two writes to the same chip select. Any value including 0 supported. Reset Source: ctl_amod_g_rst_n
  [12:8] W2R_SAMECS_DLY — Additional delay to insert between writes and reads to the same chip select. Reset Source: ctl_amod_g_rst_n
  [4:0] R2R_SAMECS_DLY — Additional delay to insert between two reads to the same chip select. Any value including 0 supported. Reset Source: ctl_amod_g_rst_n
0x628 emif_ctlcfg_DENALI_CTL_394
  [27:24] TDQSCK_MAX_F2 — Additional delay needed for tDQSCK. FC=2 Reset Source: ctl_amod_g_rst_n
  [18:16] TDQSCK_MIN_F1 — Additional delay needed for tDQSCK. FC=1 Reset Source: ctl_amod_g_rst_n
  [11:8] TDQSCK_MAX_F1 — Additional delay needed for tDQSCK. FC=1 Reset Source: ctl_amod_g_rst_n
  [2:0] TDQSCK_MIN_F0 — Additional delay needed for tDQSCK. FC=0 Reset Source: ctl_amod_g_rst_n
0x62C emif_ctlcfg_DENALI_CTL_395
  [26:24] AXI0_R_PRIORITY — Priority of read commands from AXI port 0. 0 is the highest priority. This may only be changed before initialization begins or when the controller is quiescent, there is no data in the port FIFOs, and the AXI0_FIXED_PORT_PRIORITY_ENABLE parameter is low. Reset Source: ctl_amod_g_rst_n
  [16] AXI0_FIXED_PORT_PRIORITY_ENABLE — Defines the priority control for AXI port 0 as per-port or per-command. Set to 1 for per-port with priority defined through the AXI.0._R_PRIORITY and AXI.0._W_PRIORITY parameters. Clear to 0 for per-command. Reset Source: ctl_amod_g_rst_n
  [8] AXI0_ALL_STROBES_USED_ENABLE — Enables use of the AWALLSTRB signal for AXI port 0. Set to 1 to enable. Reset Source: ctl_amod_g_rst_n
  [2:0] TDQSCK_MIN_F2 — Additional delay needed for tDQSCK. FC=2 Reset Source: ctl_amod_g_rst_n
0x630 emif_ctlcfg_DENALI_CTL_396 access per field reset 0x6000000
  [31:24] TDFI_PHY_RDLAT_F0 rw — Defines the DFI tPHY_RDLAT timing parameter [in DFI PHY clocks], the maximum cycles between a dfi_rddata_en assertion and a dfi_rddata_valid assertion. FC=0 Reset Source: ctl_amod_g_rst_n
  [16] MEM_RST_VALID ro — Register access to mem_rst_valid signal. READ-ONLY Reset Source: ctl_amod_g_rst_n
  [9:8] CKE_STATUS ro — Register access to cke_status signal. READ-ONLY Reset Source: ctl_amod_g_rst_n
  [2:0] AXI0_W_PRIORITY rw — Priority of write commands from AXI port 0. 0 is the highest priority. This may only be changed before initialization begins or when the controller is quiescent, there is no data in the port FIFOs, and the AXI0_FIXED_PORT_PRIORITY_ENABLE parameter is low. Reset Source: ctl_amod_g_rst_n
0x634 emif_ctlcfg_DENALI_CTL_397
  [20:0] TDFI_CTRLUPD_MAX_F0 — Defines the DFI tCTRLUPD_MAX timing parameter [in DFI clocks], the maximum cycles that dfi_ctrlupd_req can be asserted. If programmed to a non-zero, a timing violation will cause an interrupt and bit [0] set in the UPDATE_ERROR_STATUS parameter. FC=0 Reset Source: ctl_amod_g_rst_n
{0x0+4i} emif_ctlcfg_DENALI_CTL_{i} (i=398..401)
  [31:0] TDFI_PHYUPD_TYPE{i-398}_F0 — Defines the DFI tPHYUPD_TYPE{i-398} timing parameter [in DFI clocks], the maximum cycles that dfi_phyupd_req can assert after dfi_phyupd_ack for dfi_phyupd_type {i-398}. If programmed to a non-zero, a timing violation will cause an interrupt and bit [{i-397}] set in the UPDATE_ERROR_STATUS parameter. FC=0 Reset Source: ctl_amod_g_rst_n
0x648 emif_ctlcfg_DENALI_CTL_402
  [22:0] TDFI_PHYUPD_RESP_F0 — Defines the DFI tPHYUPD_RESP timing parameter [in DFI clocks], the maximum cycles between a dfi_phyupd_req assertion and a dfi_phyupd_ack assertion. If programmed to a non-zero, a timing violation will cause an interrupt and bit [5] set in the UPDATE_ERROR_STATUS parameter. FC=0 Reset Source: ctl_amod_g_rst_n
0x64C emif_ctlcfg_DENALI_CTL_403
  [31:0] TDFI_CTRLUPD_INTERVAL_F0 — Defines the DFI tCTRLUPD_INTERVAL timing parameter [in DFI clocks], the maximum cycles between dfi_ctrlupd_req assertions. If programmed to a non-zero, a timing violation will cause an interrupt and bit [6] set in the UPDATE_ERROR_STATUS parameter. FC=0 Reset Source: ctl_amod_g_rst_n
